# apollo4p register map
Vendor: Ambiq Micro; Series: Apollo; File version: 1.0
CPU: CM4 r1p0, little endian, MPU, FPU, I-cache, D-cache, VTOR, ITCM, DTCM, 3 interrupt priority bits, 0 interrupts
Registers are 32-bit, read-write, reset 0x0 unless marked. A register's access mark holds for its fields unless they carry their own. Offsets are from the block's base; [hi:lo] are bit positions.

## CLKGEN — Clock Generator
Base 0x40004000
0x0C OCTRL — This register includes controls for autocalibration in addition to the RTC oscillator controls.
  [7] OSEL — Selects the RTC oscillator (1=LFRC, 0=XT)This selection bit and clocking the RTC with the external crystal (XT) are inoperable in silicon revisions A and B0.
    0=RTC_XT (RTC uses the XT); 1=RTC_LFRC (RTC uses the LFRC)
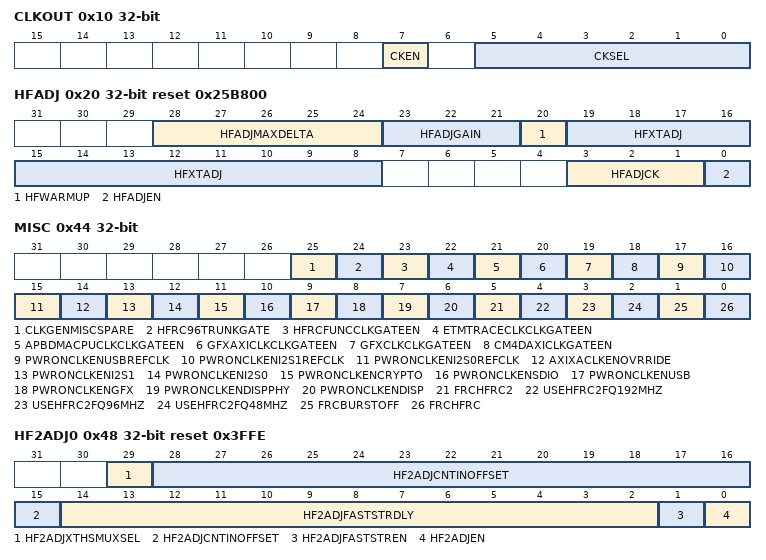
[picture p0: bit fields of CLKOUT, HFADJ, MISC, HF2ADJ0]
0x10 CLKOUT — This register enables the CLKOUT to the GPIOs, and selects the clock source to that.
  [7] CKEN — Enable the CLKOUT signal
    0=DIS (Disable CLKOUT); 1=EN (Enable CLKOUT)
  [5:0] CKSEL — CLKOUT signal select
    0=LFRC (LFRC clock source selection); 1=XT_DIV2 (XT / 2 clock source selection); 2=XT_DIV4 (XT / 4 clock source selection); 3=XT_DIV8 (XT / 8 clock source selection); 4=XT_DIV16 (XT / 16 clock source selection); 5=XT_DIV32 (XT / 32 clock source selection); 16=RTC_1Hz (1 Hz as selected in RTC); 22=XT_DIV2M (XT / 2097152 (2^21) clock source selection); 23=XT (XT clock source selection); 24=CG_100Hz (100 Hz as selected in CLKGEN); 25=HFRC_DIV2 (HFRC / 2 clock source selection); 26=HFRC_DIV8 (HFRC / 8 clock source selection); 27=HFRC_DIV16 (HFRC / 16 clock source selection); 28=HFRC_DIV32 (HFRC / 32 clock source selection); 29=HFRC_DIV128 (HFRC / 128 clock source selection); 30=HFRC_DIV256 (HFRC / 256 clock source selection); 31=HFRC_DIV512 (HFRC / 512 clock source selection); 32=HFRC_DIV1024 (HFRC / 1024 clock source selection); 34=FLASH_CLK (Flash Clock clock source selection); 35=LFRC_DIV2 (LFRC / 2 clock source selection); 36=LFRC_DIV32 (LFRC / 32 clock source selection); 37=LFRC_DIV512 (LFRC / 512 clock source selection); 38=LFRC_DIV32K (LFRC / 32768 clock source selection); 39=XT_DIV256 (XT / 256 clock source selection); 40=XT_DIV8K (XT / 8192 clock source selection); 41=XT_DIV64K (XT / 65536 (2^16) clock source selection); 42=ULFRC_DIV16 (Uncal LFRC / 16 clock source selection); 43=ULFRC_DIV128 (Uncal LFRC / 128 clock source selection); 44=ULFRC_1Hz (Uncal LFRC / 1024 clock source selection); 45=ULFRC_DIV4K (Uncal LFRC / 4096 clock source selection); 46=ULFRC_DIV1M (Uncal LFRC / 1048576 (2^20) clock source selection); 47=HFRC_DIV256K (HFRC / 262144 (2^18) clock source selection); 48=HFRC_DIV64M (HFRC / 67108864 (2^26) clock source selection); 49=LFRC_DIV1M (LFRC / 1048576 (2^20) clock source selection); 50=HFRCNE (HFRC (not autoenabled)); 51=HFRCNE_DIV8 (HFRC / 8 (not autoenabled)); 53=XTNE (XT (not autoenabled)); 54=XTNE_DIV16 (XT / 16 (not autoenabled)); 55=LFRCNE_DIV32 (LFRC / 32 (not autoenabled)); 57=LFRCNE (LFRC (not autoenabled) - Default for undefined values); 58=HFRC2 6MHz clock source selection; 59=HFRC2_12MHz (HFRC2 24MHz clock source selection); 60=HFRC2 24MHz clock source selection
0x20 HFADJ reset 0x25B800 — This register controls the HFRC adjustment. The HFRC clock can change with temperature and process corners, and this register controls the HFRC adjustment logic which reduces the fluctuations to the clock.
  [28:24] HFADJMAXDELTA — Maximum delta for HF Adjustments. 0=Disabled, 1-31=maximum delta step
    0=DISABLED (Maximum Delta function is disabled); 1=ENABLED (Maximum Delta function is enabled)
  [23:21] HFADJGAIN — Gain control for HFRC adjustment
    0=Gain_of_1 (HF Adjust with Gain of 1); 1=Gain_of_1_in_2 (HF Adjust with Gain of 0.5); 2=Gain_of_1_in_4 (HF Adjust with Gain of 0.25); 3=Gain_of_1_in_8 (HF Adjust with Gain of 0.125); 4=Gain_of_1_in_16 (HF Adjust with Gain of 0.0625); 5=Gain_of_1_in_32 (HF Adjust with Gain of 0.03125)
  [20] HFWARMUP — XT warmup period for HFRC adjustment
    0=1SEC (Autoadjust XT warmup period = 1-2 seconds); 1=2SEC (Autoadjust XT warmup period = 2-4 seconds)
  [19:8] HFXTADJ — Target HFRC adjustment value.
  [3:1] HFADJCK — Repeat period for HFRC adjustment
    0=4SEC (Autoadjust repeat period = 4 seconds); 1=16SEC (Autoadjust repeat period = 16 seconds); 2=32SEC (Autoadjust repeat period = 32 seconds); 3=64SEC (Autoadjust repeat period = 64 seconds); 4=128SEC (Autoadjust repeat period = 128 seconds); 5=256SEC (Autoadjust repeat period = 256 seconds); 6=512SEC (Autoadjust repeat period = 512 seconds); 7=1024SEC (Autoadjust repeat period = 1024 seconds)
  [0] HFADJEN — HFRC adjustment control
    0=DIS (Disable the HFRC adjustment); 1=EN (Enable the HFRC adjustment)
0x30 CLOCKENSTAT — This register provides the enable status to all the peripheral clocks.
  [31:0] CLOCKENSTAT — Clock enable status
    0x1000000=PERIPH_ALL_XTAL_EN ([24] Clock enable for PERIPH_ALL_XTAL_EN); 0x2000000=PERIPH_ALL_HFRC_EN ([25] Clock enable for PERIPH_ALL_HFRC_EN); 0x4000000=HFADJEN ([26] HFRC Adjust enabled); 0x8000000=HFRC_EN_HFADJ ([27] HFRC HFADJ enabled); 0x10000000=nOSEL ([28] ~OSEL); 0x20000000=clkout_xtal_en ([29] XTAL clkout enabled); 0x40000000=clkout_hfrc_en ([30] HFRC clkout enabled)
0x34 CLOCKEN2STAT — This is a continuation of the clock enable status.
  [31:0] CLOCKEN2STAT — Clock enable status 2
    1=ADC_CLKEN ([0] Clock enable for the ADC.); 2=APBDMA_ACTIVITY_CLKEN ([1] Clock enable for the APBDMA ACTIVITY); 4=APBDMA_AOH_CLKEN ([2] Clock enable for the APBDMA AOH DOMAIN); 8=APBDMA_AOL_CLKEN ([3] Clock enable for the APBDMA AOL DOMAIN); 16=APBDMA_APB_CLKEN ([4] Clock enable for the APBDMA_APB); 32=APBDMA_AUD_CLKEN ([5] Clock enable for the APBDMA_AUD); 64=APBDMA_CRYPTO_CLKEN ([6] Clock enable for the APBDMA_HCPA); 128=APBDMA_DBG_CLKEN ([7] Clock enable for the APBDMA_DBG); 0x100=APBDMA_DISP_CLKEN ([8] Clock enable for the APBDMA_DISP); 0x200=APBDMA_DISPPHY_CLKEN ([9] Clock enable for the APBDMA_DISPPHY); 0x400=APBDMA_DSPA_CLKEN ([10] Clock enable for the APBDMA_DSPA); 0x800=APBDMA_GFX_CLKEN ([11] Clock enable for the APBDMA_GFX); 0x1000=APBDMA_HSPA_CLKEN ([12] Clock enable for the APBDMA_HSPA); 0x2000=APBDMA_HSPB_CLKEN ([13] Clock enable for the APBDMA_HSPB); 0x4000=APBDMA_HSPC_CLKEN ([14] Clock enable for the APBDMA_HSPC); 0x8000=APBDMA_IOS_CLKEN ([15] Clock enable for the APBDMA_IOS); 0x10000=APBDMA_MSPI0_CLKEN ([16] Clock enable for the APBDMA_MSPI0); 0x20000=APBDMA_MSPI1_CLKEN ([17] Clock enable for the APBDMA_MSPI1); 0x40000=APBDMA_MSPI2_CLKEN ([18] Clock enable for the APBDMA_MSPI2); 0x80000=APBDMA_SDIO_CLKEN ([19] Clock enable for the APBDMA_SDIO); 0x100000=APBDMA_USB_CLKEN ([20] Clock enable for the APBDMA_USB); 0x200000=AUDADC_CLKEN ([21] Clock enable for the AUDADC); 0x400000=CM4_TPIU_CLKEN ([22] Clock enable for the CM4_TPIU); 0x800000=DBG_TPIU_CLKEN ([23] Clock enable for the DBG_TPIU); 0x1000000=DBG_TS_CLKEN ([24] Clock enable for the DBG_TS); 0x2000000=DISP_CLK_CLKEN ([25] Clock enable for the DISP_CLK); 0x4000000=DPHY_PLL_REF_CLKEN ([26] Clock enable for the DPHY_PLL_REF); 0x8000000=DSP_I2S0_CLKEN ([27] Clock enable for the DSP_I2S0); 0x10000000=DSP_I2S0_REFCLK_CLKEN ([28] Clock enable for the DSP_I2S0_REFCLK); 0x20000000=DSP_I2S1_CLKEN ([29] Clock enable for the DSP_I2S1); 0x40000000=DSP_I2S1_REFCLK_CLKEN ([30] Clock enable for the DSP_I2S1_REFCLK); 0x80000000=DSP_MILLI_CLKEN ([31] Clock enable for the DSP_MILLI)
0x38 CLOCKEN3STAT — This is a continuation of the clock enable status.
  [31:0] CLOCKEN3STAT — Clock enable status 3
    1=DSP_PDM0_CLKEN ([0] Clock enable for the DSP_PDM0); 2=DSP_PDM1_CLKEN ([1] Clock enable for the DSP_PDM1); 4=DSP_PDM2_CLKEN ([2] Clock enable for the DSP_PDM2); 8=DSP_PDM3_CLKEN ([3] Clock enable for the DSP_PDM3); 16=I3C0_REFCLK_CLKEN ([4] Clock enable for the I3C0_REFCLK); 32=I3C1_REFCLK_CLKEN ([5] Clock enable for the I3C1_REFCLK); 64=IOMSTRIFC0_CLKEN ([6] Clock enable for the IOMSTRIFC0); 128=IOMSTRIFC1_CLKEN ([7] Clock enable for the IO MASTER 1 IFC INTERFACE); 0x100=IOMSTRIFC2_CLKEN ([8] Clock enable for the IO MASTER 2 IFC INTERFACE); 0x200=IOMSTRIFC3_CLKEN ([9] Clock enable for the IO MASTER 3 IFC INTERFACE); 0x400=IOMSTRIFC4_CLKEN ([10] Clock enable for the IO MASTER 4 IFC INTERFACE); 0x800=IOMSTRIFC5_CLKEN ([11] Clock enable for the IO MASTER 5 IFC INTERFACE); 0x1000=IOMSTRIFC6_CLKEN ([12] Clock enable for the IO MASTER 6 IFC INTERFACE); 0x2000=IOMSTRIFC7_CLKEN ([13] Clock enable for the IO MASTER 7 IFC INTERFACE); 0x4000=RSTGEN_CLKEN ([14] Clock enable for the RSTGEN); 0x8000=RSTGEN_POS_CLKEN ([15] Clock enable for the RSTGEN); 0x10000=RTC_CLKEN ([16] Clock enable for the RTC); 0x20000=SDIO_XIN_CLKEN ([17] Clock enable for the SDIO_XIN); 0x40000=UART0HF_CLKEN ([18] Clock enable for the UART0 HF); 0x80000=UART1HF_CLKEN ([19] Clock enable for the UART1 HF); 0x100000=UART2HF_CLKEN ([20] Clock enable for the UART2 HF); 0x200000=UART3HF_CLKEN ([21] Clock enable for the UART3 HF); 0x400000=USB_REFCLK_CLKEN ([22] Clock enable for the USB_REFCLK); 0x800000=WDT_CLKEN ([23] Clock enable for the WDT)
0x44 MISC — This register controls a 'safe' mode for burst, which disables the clock when burst transition is happening. It also includes a register to force the HFRC during deep sleep. It is mainly used for debug and testing.
  [25] CLKGENMISCSPARE — Spare/Unused Chicken Bit
  [24] HFRC96TRUNKGATE — DO NOT USE. HFRC96_TRUNK_GATE. Setting this bit when BIT23=0, will kill HFRC root clock.
    0=DIS (Disable HFRC96_TRUNK_GATE); 1=EN (DO NOT USE. HFRC96_TRUNK_GATE. Setting this bit when BIT23=0, will kill HFRC root clock.)
  [23] HFRCFUNCCLKGATEEN — Chicken bit to enable clock gating on HFRC_FUNC_CLK
    0=DIS (Disable clock gate); 1=EN (Enable clock gate)
  [22] ETMTRACECLKCLKGATEEN — Chicken bit to enable clock gating on ETM TRACE CLK
    0=DIS (Disable clock gate); 1=EN (Enable clock gate)
  [21] APBDMACPUCLKCLKGATEEN — Chicken bit to enable clock gating on APB DMA CPU CLK
    0=DIS (Disable clock gate); 1=EN (Enable clock gate)
  [20] GFXAXICLKCLKGATEEN — Chicken bit to enable clock gating on GFX AXI CLK
    0=DIS (Disable clock gate); 1=EN (Enable clock gate)
  [19] GFXCLKCLKGATEEN — Chicken bit to enable clock gating on GFX CLK
    0=DIS (Disable clock gate); 1=EN (Enable clock gate)
  [18] CM4DAXICLKGATEEN — Chicken bit to enable clock gating on CM4 DAXI CLK
    0=DIS (Disable clock gate); 1=EN (Enable clock gate)
  [17] PWRONCLKENUSBREFCLK — Chicken bit to disable Rev B clock enable during reset
    0=USBREFCLKENRST (Enable USB REF Clock to run during reset); 1=DEFEATURE (Chicken bit to revert to rev A)
  [16] PWRONCLKENI2S1REFCLK — Chicken bit to disable Rev B clock enable during reset
    0=I2S1REFCLKENRST (Enable I2S instance 1 Clock to run during reset); 1=DEFEATURE (Chicken bit to revert to rev A)
  [15] PWRONCLKENI2S0REFCLK — Chicken bit to disable Rev B clock enable during reset
    0=I2S0REFCLKENRST (Enable I2S instance 0 Clock to run during reset); 1=DEFEATURE (Chicken bit to revert to rev A)
  [14] AXIXACLKENOVRRIDE — Chicken bit to disable Rev B added clock gating
    0=DEFEATURE_DISABLED (Fine grain clock gating enabled); 1=DEFEATURE (AXI Clock enabled when core is not in Sleep mode)
  [13] PWRONCLKENI2S1 — Chicken bit to disable Rev B clock enable during reset
    0=I2S1CLKENRST (Enable I2S instance 1 engine Clock to run during reset); 1=DEFEATURE (Chicken bit to revert to rev A)
  [12] PWRONCLKENI2S0 — Chicken bit to disable Rev B clock enable during reset
    0=I2S0CLKENRST (Enable I2S instance 0 engine Clock to run during reset); 1=DEFEATURE (Chicken bit to revert to rev A)
  [11] PWRONCLKENCRYPTO — Chicken bit to disable Rev B clock enable during reset
    0=CRYPTOCLKENRST (Enable Cryto engine Clock to run during reset); 1=DEFEATURE (Chicken bit to revert to rev A)
  [10] PWRONCLKENSDIO — Chicken bit to disable Rev B clock enable during reset
    0=SDIOCLKENRST (Enable SDIO Clock to run during reset); 1=DEFEATURE (Chicken bit to revert to rev A)
  [9] PWRONCLKENUSB — Chicken bit to disable Rev B clock enable during reset
    0=USBCLKENRST (Enable USB Clock to run during reset); 1=DEFEATURE (Chicken bit to revert to rev A)
  [8] PWRONCLKENGFX — Chicken bit to disable Rev B clock enable during reset
    0=GFXCLKENRST (Enable GFX Clock to run during reset); 1=DEFEATURE (Chicken bit to revert to rev A)
  [7] PWRONCLKENDISPPHY — Chicken bit to disable Rev B clock enable during reset
    0=DISPPHYCLKENRST (Enable Display Phy Clock to run during reset); 1=DEFEATURE (Chicken bit to revert to rev A)
  [6] PWRONCLKENDISP — Chicken bit to disable Rev B clock enable during reset
    0=DISPCLKENRST (Enable Display Clock to run during reset); 1=DEFEATURE (Chicken bit to revert to rev A)
  [5] FRCHFRC2 — Force HFRC2 On.Setting this bit forces HFRC2 to remain on, including in deep sleep. When changing a module's clock source to HFRC2, this bit must be set and remain set when any module is using HFRC2 as its clock.
    0=NOFRC (Do not force HFRC2 on; stops in deep sleep mode.); 1=FRC (Force HFRC2 on; runs in deep sleep mode.)
  [4] USEHFRC2FQ192MHZ — Use HFRC-192MHz or HFRC2-192MHz for MCU
    0=HFRCFQ192MHz (Use HFRC-192MHz); 1=HFRC2FQ192MHz (Use HFRC2-192MHz)
  [3] USEHFRC2FQ96MHZ — Use HFRC-96MHz or HFRC2-96MHz for DSP
    0=HFRCFQ96MHz (Use HFRC-96MHz); 1=HFRC2FQ96MHz (Use HFRC2-96MHz)
  [2] USEHFRC2FQ48MHZ — Use HFRC-48MHz or HFRC2-48MHz for DSP
    0=HFRCFQ48MHz (Use HFRC-48MHz); 1=HFRC2FQ48MHz (Use HFRC2-48MHz)
  [1] FRCBURSTOFF — Force fclk, hclk, fclk_wic and fclk_pmu to be turned off during burst transition.
    0=BURSTCLKON (fclk, hclk and fclk_wic are turned on during the burst transition); 1=BURSTCLKOFF (fclk, hclk and fclk are turned off during burst transition)
  [0] FRCHFRC — Force HFRC On .
    0=NOFRC (HFRC stops in deep sleep mode); 1=FRC (HFRC runs in deep sleep mode)
0x48 HF2ADJ0 reset 0x3FFE — This register controls hf2adj enable, fast_start enable, fast_start_delay setting and counter input offset.
  [29] HF2ADJXTHSMUXSEL — 0=XTHS 1=EXTREF select
  [28:15] HF2ADJCNTINOFFSET — Counter input offset
  [14:2] HF2ADJFASTSTRDLY — Fast_start_delay value setting
  [1] HF2ADJFASTSTREN — Fast_start_delay control
    0=DIS (Fast_start_delay disable); 1=EN (Fast_start_delay enable)
  [0] HF2ADJEN — HF2ADJ control
    0=DIS (HF2ADJ disable); 1=EN (HF2ADJ enable)
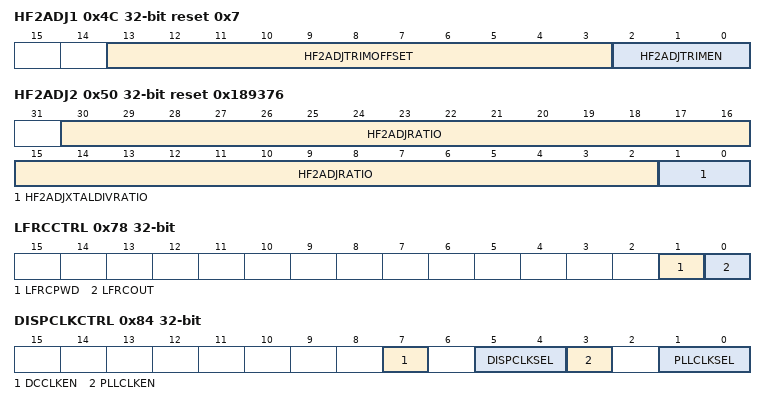
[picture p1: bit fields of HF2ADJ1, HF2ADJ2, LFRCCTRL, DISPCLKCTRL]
0x4C HF2ADJ1 reset 0x7 — This register controls hf2adj trimming enable and trimming offset.
  [13:3] HF2ADJTRIMOFFSET — HF2ADJ trimming offset. (signed number)
  [2:0] HF2ADJTRIMEN — HF2ADJ output selection
    0=TRIM_EN0 (0); 1=TRIM_EN1 (HF2ADJTRIMOUT); 2=TRIM_EN2 (HF2ADJTRIMOFFSET); 3=TRIM_EN3 (HF2ADJTRIMOUT + HF2ADJTRIMOFFSET); 4=TRIM_EN4 (HF2TUNE); 5=TRIM_EN5 (HF2ADJTRIMOUT + HF2TUNE); 6=TRIM_EN6 (HF2ADJTRIMOFFSET + HF2TUNE); 7=TRIM_EN7 (HF2ADJTRIMOUT + HF2ADJTRIMOFFSET + HF2TUNE)
0x50 HF2ADJ2 reset 0x189376 — This register controls xtal32m divider ratio and HF2ADJ ration setting.
  [30:2] HF2ADJRATIO — HF2ADJ ratio setting.
  [1:0] HF2ADJXTALDIVRATIO — XTAL32MHz divider ratio for HF2ADJ.
    0=XTAL32M (XTAL32MHz); 1=XTAL32M_DIV2 (XTAL32MHz / 2); 2=XTAL32M_DIV4 (XTAL32MHz / 4); 3=XTAL32M_DIV8 (XTAL32MHz / 8)
0x54 HF2VAL — This register provides the read back of the HF2TUNE
  [10:0] HF2ADJTRIMOUT — HF2ADJ trimming output
0x78 LFRCCTRL — LFRC control
  [1] LFRCPWD — Power down LFRC
  [0] LFRCOUT — Disable LFRC output
0x84 DISPCLKCTRL — Provides ability to select the PLL reference clock, and derivative of the display clock
  [7] DCCLKEN — Enable for the PLL clock through clkgen
  [5:4] DISPCLKSEL — Selection for PLL reference clock.
    0=OFF (Static value of 0 selected for DPHY clock input); 1=HFRC48 (48MHz sourced from the HFRC); 2=HFRC96 (96MHz sourced from the HFRC); 3=DPHYPLL
  [3] PLLCLKEN — Enable for the PLL clock through clkgen
  [1:0] PLLCLKSEL — Selection for PLL reference clock.
    0=OFF (Static value of 0 selected for DPHY clock input); 1=HFRC12 (12MHz sourced from the HFRC); 2=HFRC6 (6MHz sourced from the HFRC); 3=HFXT_16 (High Frequency XTAL input (16MHz))
0x88 CLKGENSPARES — CLKGEN Spare Regs
  [31:0] CLKGENSPARES — Placeholer spare registes that can be used as needed for future use
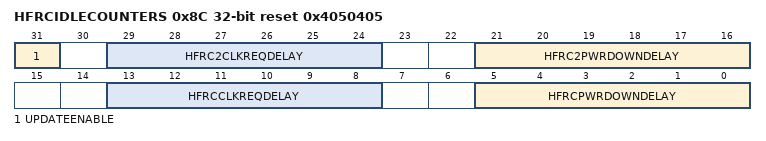
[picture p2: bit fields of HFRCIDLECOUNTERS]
0x8C HFRCIDLECOUNTERS reset 0x4050405 — Provides SW controlled # idle cycles before powering down HFRC, HFRC2., core clock enable(s)
  [31] UPDATEENABLE — usage : Clear UPDATEENABLE or 1'b0; Update other bits fields of this register. Set this register to 1'b1 for HW to update.
  [29:24] HFRC2CLKREQDELAY — Enable for the PLL clock through clkgen
  [21:16] HFRC2PWRDOWNDELAY — Idle counter for HFRC2 POWER DOWN DELAY
  [13:8] HFRCCLKREQDELAY — Idle counter for HFRC CLK REQ DELAY
  [5:0] HFRCPWRDOWNDELAY — Idle counter for HFRC POWER DOWN DELAY
0x100 INTRPTEN — Set bits in this register to allow this module to generate the corresponding interrupt.
  [0] OF — XT Oscillator Fail interrupt
0x104 INTRPTSTAT — Read bits from this register to discover the cause of a recent interrupt.
  [0] OF — XT Oscillator Fail interrupt
0x108 INTRPTCLR — Write a 1 to a bit in this register to clear the interrupt status associated with that bit.
  [0] OF — XT Oscillator Fail interrupt
0x10C INTRPTSET — Write a 1 to a bit in this register to instantly generate an interrupt from this module. (Generally used for testing purposes).
  [0] OF — XT Oscillator Fail interrupt

## Notices in the file
Copyright (C) 2012-2014 ARM Limited. All rights reserved.
Purpose: System Viewer Description (SVD) Example (Schema Version 1.1)
This is a description of a none-existent and incomplete device
for demonstration purposes only.
Redistribution and use in source and binary forms, with or without
modification, are permitted provided that the following conditions are met:
- Redistributions of source code must retain the above copyright
notice, this list of conditions and the following disclaimer.
- Redistributions in binary form must reproduce the above copyright
notice, this list of conditions and the following disclaimer in the
documentation and/or other materials provided with the distribution.
- Neither the name of ARM nor the names of its contributors may be used
to endorse or promote products derived from this software without
specific prior written permission.
THIS SOFTWARE IS PROVIDED BY THE COPYRIGHT HOLDERS AND CONTRIBUTORS "AS IS"
AND ANY EXPRESS OR IMPLIED WARRANTIES, INCLUDING, BUT NOT LIMITED TO, THE
IMPLIED WARRANTIES OF MERCHANTABILITY AND FITNESS FOR A PARTICULAR PURPOSE
ARE DISCLAIMED. IN NO EVENT SHALL COPYRIGHT HOLDERS AND CONTRIBUTORS BE
LIABLE FOR ANY DIRECT, INDIRECT, INCIDENTAL, SPECIAL, EXEMPLARY, OR
CONSEQUENTIAL DAMAGES (INCLUDING, BUT NOT LIMITED TO, PROCUREMENT OF
SUBSTITUTE GOODS OR SERVICES; LOSS OF USE, DATA, OR PROFITS; OR BUSINESS
INTERRUPTION) HOWEVER CAUSED AND ON ANY THEORY OF LIABILITY, WHETHER IN
CONTRACT, STRICT LIABILITY, OR TORT (INCLUDING NEGLIGENCE OR OTHERWISE)
ARISING IN ANY WAY OUT OF THE USE OF THIS SOFTWARE, EVEN IF ADVISED OF THE
POSSIBILITY OF SUCH DAMAGE.
